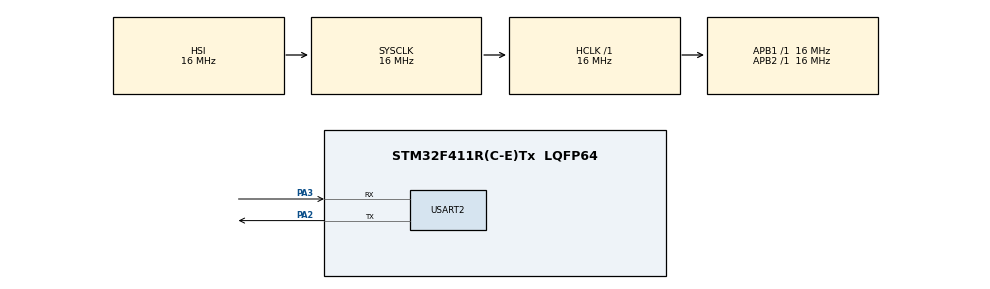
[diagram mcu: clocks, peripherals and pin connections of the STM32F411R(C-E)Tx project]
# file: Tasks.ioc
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FREERTOS.Tasks01=Task1,24,256,StartTask1,Default,NULL,Dynamic,NULL,NULL;Task2,24,256,StartTask2,Default,NULL,Dynamic,NULL,NULL
FREERTOS.configUSE_NEWLIB_REENTRANT=1
Mcu.Family=STM32F4
Mcu.Name=STM32F411R(C-E)Tx
Mcu.Package=LQFP64
NVIC.PriorityGroup=NVIC_PRIORITYGROUP_4
NVIC.TIM1_UP_TIM10_IRQn=true\:15\:0\:false\:false\:true\:false\:false\:true\:true
NVIC.TimeBase=TIM1_UP_TIM10_IRQn
NVIC.TimeBaseIP=TIM10
PA13.Mode=Serial_Wire
PA13.Signal=SYS_JTMS-SWDIO
PA14.Mode=Serial_Wire
PA14.Signal=SYS_JTCK-SWCLK
PA2.Mode=Asynchronous
PA2.Signal=USART2_TX
PA3.Mode=Asynchronous
PA3.Signal=USART2_RX
ProjectManager.HeapSize=0x200
ProjectManager.StackSize=0x400
ProjectManager.TargetToolchain=STM32CubeIDE
RCC.AHBFreq_Value=16000000
RCC.APB1Freq_Value=16000000
RCC.APB2Freq_Value=16000000
RCC.CortexFreq_Value=16000000
RCC.HSE_VALUE=25000000
RCC.HSI_VALUE=16000000
RCC.LSE_VALUE=32768
RCC.SYSCLKFreq_VALUE=16000000
RCC.VCOOutputFreq_Value=192000000
USART2.VirtualMode=VM_ASYNC
VP_FREERTOS_VS_CMSIS_V2.Mode=CMSIS_V2
VP_SYS_VS_tim10.Mode=TIM10
board=custom

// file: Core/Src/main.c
/* USER CODE BEGIN Header */
/**
  ******************************************************************************
  * @file           : main.c
  * @brief          : Main program body
  ******************************************************************************
  * @attention
  *
  * Copyright (c) 2025 STMicroelectronics.
  * All rights reserved.
  *
  * This software is licensed under terms that can be found in the LICENSE file
  * in the root directory of this software component.
  * If no LICENSE file comes with this software, it is provided AS-IS.
  *
  ******************************************************************************
  */
/* USER CODE END Header */
#include "main.h"
#include "cmsis_os.h"

/* USER CODE BEGIN Includes */
#include "stdio.h"
/* USER CODE END Includes */

UART_HandleTypeDef huart2;

/* Definitions for Task1 */
osThreadId_t Task1Handle;
const osThreadAttr_t Task1_attributes = {
  .name = "Task1",
  .stack_size = 128 * 4,
  .priority = (osPriority_t) osPriorityNormal,
};
/* Definitions for Task2 */
osThreadId_t Task2Handle;
const osThreadAttr_t Task2_attributes = {
  .name = "Task2",
  .stack_size = 128 * 4,
  .priority = (osPriority_t) osPriorityNormal,
};

void SystemClock_Config(void);
static void MX_GPIO_Init(void);
static void MX_USART2_UART_Init(void);
void StartTask1(void *argument);
void StartTask2(void *argument);

/* USER CODE BEGIN PFP */
int _write(int file, char *ptr, int len)
{
	int DataIdx;
	for(DataIdx = 0; DataIdx < len; DataIdx++)
	{
		HAL_UART_Transmit(&huart2, (uint8_t *)ptr++, 1, 100);
	}
	return len;
}
/* USER CODE END PFP */

int main(void)
{

  /* MCU Configuration--------------------------------------------------------*/

  /* Reset of all peripherals, Initializes the Flash interface and the Systick. */
  HAL_Init();

  /* Configure the system clock */
  SystemClock_Config();

  /* Initialize all configured peripherals */
  MX_GPIO_Init();
  MX_USART2_UART_Init();

  /* Init scheduler */
  osKernelInitialize();

  /* Create the thread(s) */
  /* creation of Task1 */
  Task1Handle = osThreadNew(StartTask1, NULL, &Task1_attributes);

  /* creation of Task2 */
  Task2Handle = osThreadNew(StartTask2, NULL, &Task2_attributes);

  /* Start scheduler */
  osKernelStart();

  /* We should never get here as control is now taken by the scheduler */
  /* Infinite loop */
  while (1)
  {

  }
}

void SystemClock_Config(void)
{
  RCC_OscInitTypeDef RCC_OscInitStruct = {0};
  RCC_ClkInitTypeDef RCC_ClkInitStruct = {0};

  /** Configure the main internal regulator output voltage
  */
  __HAL_RCC_PWR_CLK_ENABLE();
  __HAL_PWR_VOLTAGESCALING_CONFIG(PWR_REGULATOR_VOLTAGE_SCALE1);

  /** Initializes the RCC Oscillators according to the specified parameters
  * in the RCC_OscInitTypeDef structure.
  */
  RCC_OscInitStruct.OscillatorType = RCC_OSCILLATORTYPE_HSI;
  RCC_OscInitStruct.HSIState = RCC_HSI_ON;
  RCC_OscInitStruct.HSICalibrationValue = RCC_HSICALIBRATION_DEFAULT;
  RCC_OscInitStruct.PLL.PLLState = RCC_PLL_NONE;
  if (HAL_RCC_OscConfig(&RCC_OscInitStruct) != HAL_OK)
  {
    Error_Handler();
  }

  /** Initializes the CPU, AHB and APB buses clocks
  */
  RCC_ClkInitStruct.ClockType = RCC_CLOCKTYPE_HCLK|RCC_CLOCKTYPE_SYSCLK
                              |RCC_CLOCKTYPE_PCLK1|RCC_CLOCKTYPE_PCLK2;
  RCC_ClkInitStruct.SYSCLKSource = RCC_SYSCLKSOURCE_HSI;
  RCC_ClkInitStruct.AHBCLKDivider = RCC_SYSCLK_DIV1;
  RCC_ClkInitStruct.APB1CLKDivider = RCC_HCLK_DIV1;
  RCC_ClkInitStruct.APB2CLKDivider = RCC_HCLK_DIV1;

  if (HAL_RCC_ClockConfig(&RCC_ClkInitStruct, FLASH_LATENCY_0) != HAL_OK)
  {
    Error_Handler();
  }
}

static void MX_USART2_UART_Init(void)
{

  huart2.Instance = USART2;
  huart2.Init.BaudRate = 115200;
  huart2.Init.WordLength = UART_WORDLENGTH_8B;
  huart2.Init.StopBits = UART_STOPBITS_1;
  huart2.Init.Parity = UART_PARITY_NONE;
  huart2.Init.Mode = UART_MODE_TX_RX;
  huart2.Init.HwFlowCtl = UART_HWCONTROL_NONE;
  huart2.Init.OverSampling = UART_OVERSAMPLING_16;
  if (HAL_UART_Init(&huart2) != HAL_OK)
  {
    Error_Handler();
  }

}

static void MX_GPIO_Init(void)
{

  /* GPIO Ports Clock Enable */
  __HAL_RCC_GPIOA_CLK_ENABLE();

}

void StartTask1(void *argument)
{
  /* USER CODE BEGIN 5 */
  /* Infinite loop */
  for(;;)
  {
	printf("1\n");
    osDelay(1000);
  }
  /* USER CODE END 5 */
}

void StartTask2(void *argument)
{
  /* USER CODE BEGIN StartTask2 */
  /* Infinite loop */
  for(;;)
  {
	printf("2\n");
    osDelay(1000);
  }
  /* USER CODE END StartTask2 */
}

void HAL_TIM_PeriodElapsedCallback(TIM_HandleTypeDef *htim)
{
  if (htim->Instance == TIM10) {
    HAL_IncTick();
  }
}

void Error_Handler(void)
{
  __disable_irq();
  while (1)
  {
  }
}
